AUTOSAR XML (schema 00047)
package /LaneGuidance_pkg/LaneGuidance_swc
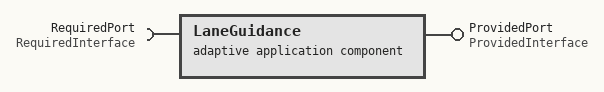
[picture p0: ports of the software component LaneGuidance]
  adaptive application sw component type LaneGuidance
    require port RequiredPort: required-interface=RequiredInterface
      required-com-specs:
        data-element=LeftLaneDistance, queue-length=10
        data-element=LeftTurnIndicator, queue-length=10
        data-element=RightLaneDistance, queue-length=10
        data-element=RightTurnIndicator, queue-length=10
        data-element=LeftCarInBlindSpot, queue-length=10
        data-element=RightCarInBlindSpot, queue-length=10
    provide port ProvidedPort: provided-com-specs=[data-element=LeftHazardIndicator, data-element=RightHazardIndicator], provided-interface=ProvidedInterface
package /LaneGuidance_pkg/LaneGuidance_if
  service interface ProvidedInterface
    namespaces:
      symbol props company
      symbol props chassis
      symbol props provided
    events:
      data LeftHazardIndicator: category=VALUE, sw-calibration-access=READ-ONLY, sw-impl-policy=QUEUED, type=Double
      data RightHazardIndicator: category=VALUE, sw-calibration-access=READ-ONLY, sw-impl-policy=QUEUED, type=Double
  service interface RequiredInterface
    namespaces:
      symbol props company
      symbol props chassis
      symbol props required
    events:
      6 x data, all with category=VALUE, sw-calibration-access=READ-ONLY, sw-impl-policy=QUEUED, type=Double:
        LeftLaneDistance
        LeftTurnIndicator
        RightLaneDistance
        RightTurnIndicator
        LeftCarInBlindSpot
        RightCarInBlindSpot
package /LaneGuidance_pkg/LaneGuidance_dt
  std cpp implementation data type Double: category=VALUE, cpp-template-argument=double
package /LaneGuidance_pkg/LaneGuidance_dt/SwBaseTypes
  std cpp implementation data type double: category=VALUE
